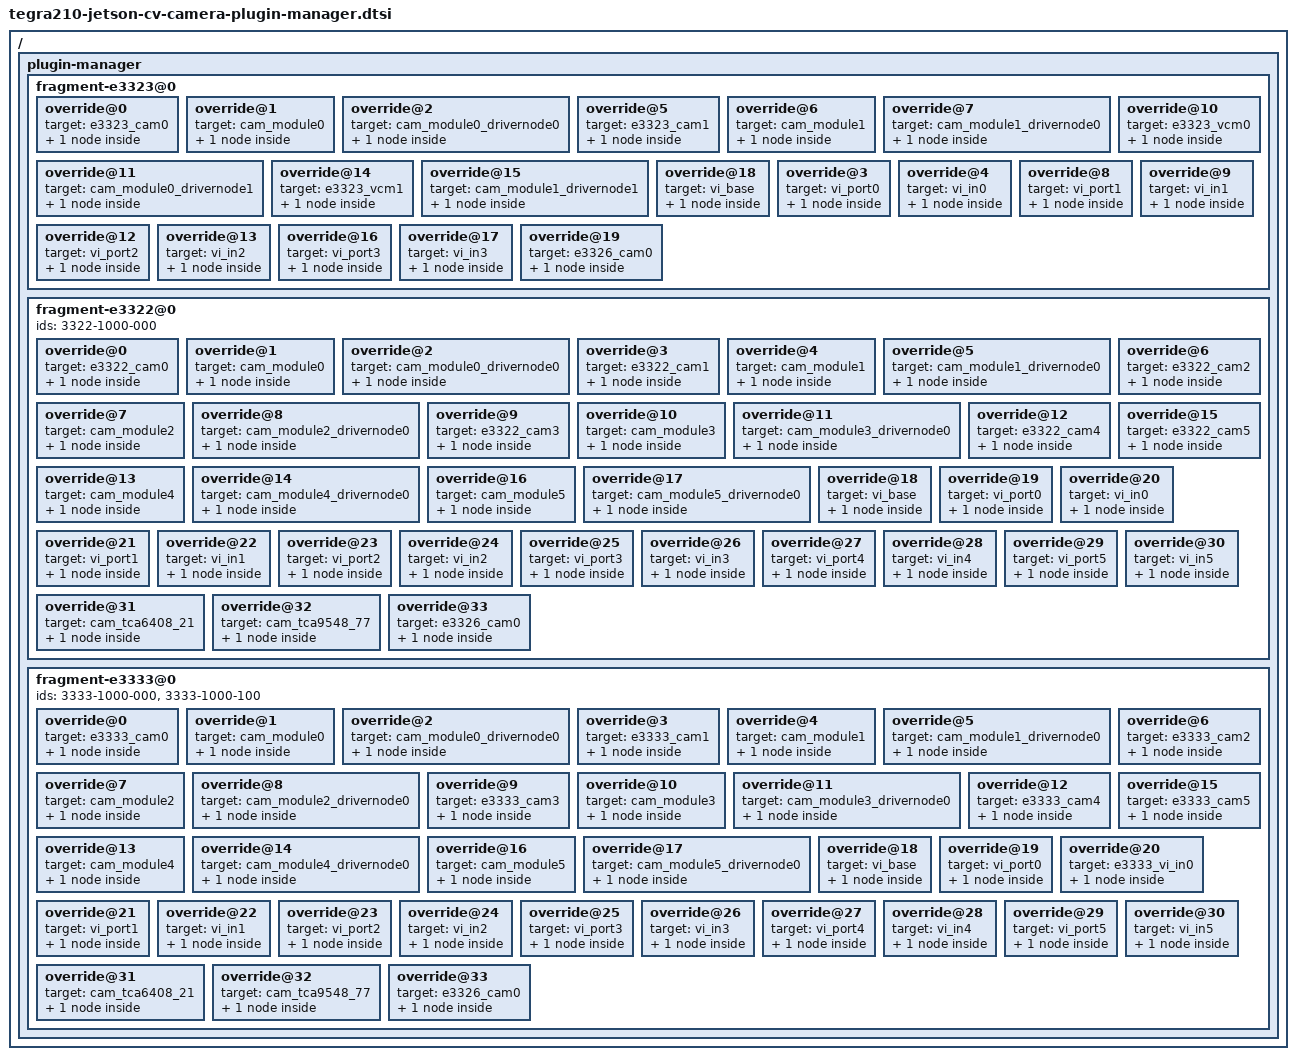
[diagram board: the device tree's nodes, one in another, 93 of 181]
/*
 * Copyright (c) 2016, NVIDIA CORPORATION.  All rights reserved.
 *
 * This program is free software; you can redistribute it and/or modify
 * it under the terms of the GNU General Public License as published by
 * the Free Software Foundation; version 2 of the License.
 *
 * This program is distributed in the hope that it will be useful, but WITHOUT
 * ANY WARRANTY; without even the implied warranty of MERCHANTABILITY or
 * FITNESS FOR A PARTICULAR PURPOSE.  See the GNU General Public License for
 * more details.
 *
 */
/ {
	/* camera plugin-manager */
	plugin-manager {
		/* E3326 camera board is enabled by default */

		/* E3323 camera board */
		fragment-e3323@0 {
			ids = "3323-1000-A00", "3323-1000-A01", "3323-1000-100";
			/* enable E3323 camera 0 */
			override@0 {
				target = <&e3323_cam0>;
				_overlay_ {
					status = "okay";
				};
			};
			override@1 {
				target = <&cam_module0>;
				_overlay_ {
					status = "okay";
					badge = "e3323_bottom_CH06P1";
					position = "bottom";
					orientation = "3";
				};
			};
			override@2 {
				target = <&cam_module0_drivernode0>;
				_overlay_ {
					status = "okay";
					pcl_id = "v4l2_sensor";
					proc-device-tree = "/proc/device-tree/host1x/i2c@546c0000/ov23850_a@10";
				};
			};
			/* enable E3323 camera 1 */
			override@5 {
				target = <&e3323_cam1>;
				_overlay_ {
					status = "okay";
				};
			};
			override@6 {
				target = <&cam_module1>;
				_overlay_ {
					status = "okay";
					badge = "e3323_top_CH06P1";
					position = "top";
					orientation = "3";
				};
			};
			override@7 {
				target = <&cam_module1_drivernode0>;
				_overlay_ {
					status = "okay";
					pcl_id = "v4l2_sensor";
					proc-device-tree = "/proc/device-tree/i2c@7000c000/ov23850_c@36";
				};
			};
			/* enable E3323 focuser 0 */
			override@10 {
				target = <&e3323_vcm0>;
				_overlay_ {
					status = "okay";
				};
			};
			override@11 {
				target = <&cam_module0_drivernode1>;
				_overlay_ {
					status = "okay";
					pcl_id = "v4l2_focuser";
					proc-device-tree = "/proc/device-tree/host1x/i2c@546c0000/lc898212@72";
				};
			};
			/* enable E3323 focuser 1 */
			override@14 {
				target = <&e3323_vcm1>;
				_overlay_ {
					status = "okay";
				};
			};
			override@15 {
				target = <&cam_module1_drivernode1>;
				_overlay_ {
					status = "okay";
					pcl_id = "v4l2_focuser";
					proc-device-tree = "/proc/device-tree/i2c@7000c000/lc898212@72";
				};
			};
			/* enable VI ports */
			override@18 {
				target = <&vi_base>;
				_overlay_ {
					num-channels=<4>;
				};
			};
			override@3 {
				target = <&vi_port0>;
				_overlay_ {
					status = "okay";
				};
			};
			override@4 {
				target = <&vi_in0>;
				_overlay_ {
					status = "okay";
					csi-port = <0>;
					bus-width = <4>;
					remote-endpoint = <&ov23850_out0>;
				};
			};
			override@8 {
				target = <&vi_port1>;
				_overlay_ {
					status = "okay";
				};
			};
			override@9 {
				target = <&vi_in1>;
				_overlay_ {
					status = "okay";
					csi-port = <2>;
					bus-width = <4>;
					remote-endpoint = <&ov23850_out1>;
				};
			};
			override@12 {
				target = <&vi_port2>;
				_overlay_ {
					status = "okay";
				};
			};
			override@13 {
				target = <&vi_in2>;
				_overlay_ {
					status = "okay";
					remote-endpoint = <&lc898212_out0>;
				};
			};
			override@16 {
				target = <&vi_port3>;
				_overlay_ {
					status = "okay";
				};
			};
			override@17 {
				target = <&vi_in3>;
				_overlay_ {
					status = "okay";
					remote-endpoint = <&lc898212_out1>;
				};
			};
			/* disable E3326 camera board*/
			override@19 {
				target = <&e3326_cam0>;
				_overlay_ {
					status = "disabled";
				};
			};
		};

		/* E3322 camera board */
		fragment-e3322@0 {
			ids = "3322-1000-000";
			/* enable E3322 camera 0 */
			override@0 {
				target = <&e3322_cam0>;
				_overlay_ {
					status = "okay";
				};
			};
			override@1 {
				target = <&cam_module0>;
				_overlay_ {
					status = "okay";
					badge = "e3322_bottomleft_A815P2";
					position = "bottomleft";
					orientation = "1";
				};
			};
			override@2 {
				target = <&cam_module0_drivernode0>;
				_overlay_ {
					status = "okay";
					pcl_id = "v4l2_sensor";
					proc-device-tree = "/proc/device-tree/host1x/i2c@546c0000/tca9548@77/i2c@0/imx219_a@10";
				};
			};
			/* enable E3322 camera 1 */
			override@3 {
				target = <&e3322_cam1>;
				_overlay_ {
					status = "okay";
				};
			};
			override@4 {
				target = <&cam_module1>;
				_overlay_ {
					status = "okay";
					badge = "e3322_centerleft_A815P2";
					position = "centerleft";
					orientation = "1";
				};
			};
			override@5 {
				target = <&cam_module1_drivernode0>;
				_overlay_ {
					status = "okay";
					pcl_id = "v4l2_sensor";
					proc-device-tree = "/proc/device-tree/host1x/i2c@546c0000/tca9548@77/i2c@1/imx219_b@10";
				};
			};
			/* E3322 camera 2 */
			override@6 {
				target = <&e3322_cam2>;
				_overlay_ {
					status = "okay";
				};
			};
			override@7 {
				target = <&cam_module2>;
				_overlay_ {
					status = "okay";
					badge = "e3322_centerright_A815P2";
					position = "centerright";
					orientation = "1";
				};
			};
			override@8 {
				target = <&cam_module2_drivernode0>;
				_overlay_ {
					status = "okay";
					pcl_id = "v4l2_sensor";
					proc-device-tree = "/proc/device-tree/host1x/i2c@546c0000/tca9548@77/i2c@2/imx219_c@10";
				};
			};
			/* E3322 camera 3 */
			override@9 {
				target = <&e3322_cam3>;
				_overlay_ {
					status = "okay";
				};
			};
			override@10 {
				target = <&cam_module3>;
				_overlay_ {
					status = "okay";
					badge = "e3322_topleft_A815P2";
					position = "topleft";
					orientation = "1";
				};
			};
			override@11 {
				target = <&cam_module3_drivernode0>;
				_overlay_ {
					status = "okay";
					pcl_id = "v4l2_sensor";
					proc-device-tree = "/proc/device-tree/host1x/i2c@546c0000/tca9548@77/i2c@3/imx219_d@10";
				};
			};
			/* E3322 camera 4 */
			override@12 {
				target = <&e3322_cam4>;
				_overlay_ {
					status = "okay";
				};
			};
			override@13 {
				target = <&cam_module4>;
				_overlay_ {
					status = "okay";
					badge = "e3322_bottomright_A815P2";
					position = "bottomright";
					orientation = "1";
				};
			};
			override@14 {
				target = <&cam_module4_drivernode0>;
				_overlay_ {
					status = "okay";
					pcl_id = "v4l2_sensor";
					proc-device-tree = "/proc/device-tree/host1x/i2c@546c0000/tca9548@77/i2c@4/imx219_e@10";
				};
			};
			/* E3322 camera 5 */
			override@15 {
				target = <&e3322_cam5>;
				_overlay_ {
					status = "okay";
				};
			};
			override@16 {
				target = <&cam_module5>;
				_overlay_ {
					status = "okay";
					badge = "e3322_topright_A815P2";
					position = "topright";
					orientation = "1";
				};
			};
			override@17 {
				target = <&cam_module5_drivernode0>;
				_overlay_ {
					status = "okay";
					pcl_id = "v4l2_sensor";
					proc-device-tree = "/proc/device-tree/host1x/i2c@546c0000/tca9548@77/i2c@5/imx219_f@10";
				};
			};
			/* Enable VI ports */
			override@18 {
				target = <&vi_base>;
				_overlay_ {
					num-channels=<6>;
				};
			};
			override@19 {
				target = <&vi_port0>;
				_overlay_ {
					status = "okay";
				};
			};
			override@20 {
				target = <&vi_in0>;
				_overlay_ {
					status = "okay";
					csi-port = <0>;
					bus-width = <2>;
					remote-endpoint = <&imx219_out0>;
				};
			};
			override@21 {
				target = <&vi_port1>;
				_overlay_ {
					status = "okay";
				};
			};
			override@22 {
				target = <&vi_in1>;
				_overlay_ {
					status = "okay";
					csi-port = <1>;
					bus-width = <2>;
					remote-endpoint = <&imx219_out1>;
				};
			};
			override@23 {
				target = <&vi_port2>;
				_overlay_ {
					status = "okay";
				};
			};
			override@24 {
				target = <&vi_in2>;
				_overlay_ {
					status = "okay";
					csi-port = <2>;
					bus-width = <2>;
					remote-endpoint = <&imx219_out2>;
				};
			};
			override@25 {
				target = <&vi_port3>;
				_overlay_ {
					status = "okay";
				};
			};
			override@26 {
				target = <&vi_in3>;
				_overlay_ {
					status = "okay";
					csi-port = <3>;
					bus-width = <2>;
					remote-endpoint = <&imx219_out3>;
				};
			};
			override@27 {
				target = <&vi_port4>;
				_overlay_ {
					status = "okay";
				};
			};
			override@28 {
				target = <&vi_in4>;
				_overlay_ {
					status = "okay";
					csi-port = <4>;
					bus-width = <2>;
					remote-endpoint = <&imx219_out4>;
				};
			};
			override@29 {
				target = <&vi_port5>;
				_overlay_ {
					status = "okay";
				};
			};
			override@30 {
				target = <&vi_in5>;
				_overlay_ {
					status = "okay";
					csi-port = <5>;
					bus-width = <2>;
					remote-endpoint = <&imx219_out5>;
				};
			};
			/* Enable TCA6408 GPIO expander */
			override@31 {
				target = <&cam_tca6408_21>;
				_overlay_ {
					status = "okay";
				};
			};
			/* Enable TCA9548 I2C mux */
			override@32 {
				target = <&cam_tca9548_77>;
				_overlay_ {
					status = "okay";
				};
			};
			/* Disable E3326 camera board */
			override@33 {
				target = <&e3326_cam0>;
				_overlay_ {
					status = "disabled";
				};
			};
		};

		/* E3333 camera board */
		fragment-e3333@0 {
			ids = "3333-1000-000", "3333-1000-100";
			/* Enable E3333 camera 0 */
			override@0 {
				target = <&e3333_cam0>;
				_overlay_ {
					status = "okay";
				};
			};
			override@1 {
				target = <&cam_module0>;
				_overlay_ {
					status = "okay";
					badge = "e3333_bottomleft_P5V27C";
					position = "bottomleft";
					orientation = "1";
				};
			};
			override@2 {
				target = <&cam_module0_drivernode0>;
				_overlay_ {
					status = "okay";
					pcl_id = "v4l2_sensor";
					proc-device-tree = "/proc/device-tree/host1x/i2c@546c0000/tca9548@77/i2c@0/ov5693_a@36";
				};
			};
			/* Enable E3333 camera 1 */
			override@3 {
				target = <&e3333_cam1>;
				_overlay_ {
					status = "okay";
				};
			};
			override@4 {
				target = <&cam_module1>;
				_overlay_ {
					status = "okay";
					badge = "e3333_centerleft_P5V27C";
					position = "centerleft";
					orientation = "1";
				};
			};
			override@5 {
				target = <&cam_module1_drivernode0>;
				_overlay_ {
					status = "okay";
					pcl_id = "v4l2_sensor";
					proc-device-tree = "/proc/device-tree/host1x/i2c@546c0000/tca9548@77/i2c@1/ov5693_b@36";
				};
			};
			/* Enable E3333 camera 2 */
			override@6 {
				target = <&e3333_cam2>;
				_overlay_ {
					status = "okay";
				};
			};
			override@7 {
				target = <&cam_module2>;
				_overlay_ {
					status = "okay";
					badge = "e3333_centerright_P5V27C";
					position = "centerright";
					orientation = "1";
				};
			};
			override@8 {
				target = <&cam_module2_drivernode0>;
				_overlay_ {
					status = "okay";
					pcl_id = "v4l2_sensor";
					proc-device-tree = "/proc/device-tree/host1x/i2c@546c0000/tca9548@77/i2c@2/ov5693_c@36";
				};
			};
			/* Enable E3333 camera 3 */
			override@9 {
				target = <&e3333_cam3>;
				_overlay_ {
					status = "okay";
				};
			};
			override@10 {
				target = <&cam_module3>;
				_overlay_ {
					status = "okay";
					badge = "e3333_topleft_P5V27C";
					position = "topleft";
					orientation = "1";
				};
			};
			override@11 {
				target = <&cam_module3_drivernode0>;
				_overlay_ {
					status = "okay";
					pcl_id = "v4l2_sensor";
					proc-device-tree = "/proc/device-tree/host1x/i2c@546c0000/tca9548@77/i2c@3/ov5693_d@36";
				};
			};
			/* Enable E3333 camera 4 */
			override@12 {
				target = <&e3333_cam4>;
				_overlay_ {
					status = "okay";
				};
			};
			override@13 {
				target = <&cam_module4>;
				_overlay_ {
					status = "okay";
					badge = "e3333_bottomright_P5V27C";
					position = "bottomright";
					orientation = "1";
				};
			};
			override@14 {
				target = <&cam_module4_drivernode0>;
				_overlay_ {
					status = "okay";
					pcl_id = "v4l2_sensor";
					proc-device-tree = "/proc/device-tree/host1x/i2c@546c0000/tca9548@77/i2c@4/ov5693_e@36";
				};
			};
			/* Enable E3333 camera 5 */
			override@15 {
				target = <&e3333_cam5>;
				_overlay_ {
					status = "okay";
				};
			};
			override@16 {
				target = <&cam_module5>;
				_overlay_ {
					status = "okay";
					badge = "e3333_topright_P5V27C";
					position = "topright";
					orientation = "1";
				};
			};
			override@17 {
				target = <&cam_module5_drivernode0>;
				_overlay_ {
					status = "okay";
					pcl_id = "v4l2_sensor";
					proc-device-tree = "/proc/device-tree/host1x/i2c@546c0000/tca9548@77/i2c@5/ov5693_f@36";
				};
			};
			/* Enable VI ports */
			override@18 {
				target = <&vi_base>;
				_overlay_ {
					num-channels=<6>;
				};
			};
			override@19 {
				target = <&vi_port0>;
				_overlay_ {
					status = "okay";
				};
			};
			override@20 {
				target = <&e3333_vi_in0>;
				_overlay_ {
					status = "okay";
					csi-port = <0>;
					bus-width = <2>;
					remote-endpoint = <&e3333_ov5693_out0>;
				};
			};
			override@21 {
				target = <&vi_port1>;
				_overlay_ {
					status = "okay";
				};
			};
			override@22 {
				target = <&vi_in1>;
				_overlay_ {
					status = "okay";
					csi-port = <1>;
					bus-width = <2>;
					remote-endpoint = <&e3333_ov5693_out1>;
				};
			};
			override@23 {
				target = <&vi_port2>;
				_overlay_ {
					status = "okay";
				};
			};
			override@24 {
				target = <&vi_in2>;
				_overlay_ {
					status = "okay";
					csi-port = <2>;
					bus-width = <2>;
					remote-endpoint = <&e3333_ov5693_out2>;
				};
			};
			override@25 {
				target = <&vi_port3>;
				_overlay_ {
					status = "okay";
				};
			};
			override@26 {
				target = <&vi_in3>;
				_overlay_ {
					status = "okay";
					csi-port = <3>;
					bus-width = <2>;
					remote-endpoint = <&e3333_ov5693_out3>;
				};
			};
			override@27 {
				target = <&vi_port4>;
				_overlay_ {
					status = "okay";
				};
			};
			override@28 {
				target = <&vi_in4>;
				_overlay_ {
					status = "okay";
					csi-port = <4>;
					bus-width = <2>;
					remote-endpoint = <&e3333_ov5693_out4>;
				};
			};
			override@29 {
				target = <&vi_port5>;
				_overlay_ {
					status = "okay";
				};
			};
			override@30 {
				target = <&vi_in5>;
				_overlay_ {
					status = "okay";
					csi-port = <5>;
					bus-width = <2>;
					remote-endpoint = <&e3333_ov5693_out5>;
				};
			};
			/* Enable TCA6408 GPIO expander */
			override@31 {
				target = <&cam_tca6408_21>;
				_overlay_ {
					status = "okay";
				};
			};
			/* Enable TCA9548 I2C mux */
			override@32 {
				target = <&cam_tca9548_77>;
				_overlay_ {
					status = "okay";
				};
			};
			/* Disable E3326 camera board */
			override@33 {
				target = <&e3326_cam0>;
				_overlay_ {
					status = "disabled";
				};
			};
		};
	};
};
